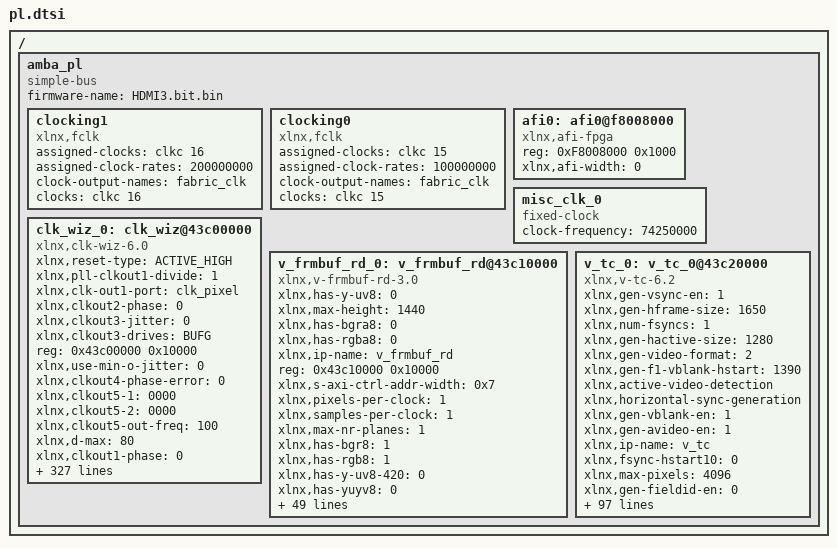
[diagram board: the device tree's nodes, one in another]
/ {
	amba_pl: amba_pl {
		ranges;
		compatible = "simple-bus";
		#address-cells = <1>;
		#size-cells = <1>;
		firmware-name = "HDMI3.bit.bin";
		clocking1: clocking1 {
			compatible = "xlnx,fclk";
			assigned-clocks = <&clkc 16>;
			assigned-clock-rates = <200000000>;
			#clock-cells = <0>;
			clock-output-names = "fabric_clk";
			clocks = <&clkc 16>;
		};
		clocking0: clocking0 {
			compatible = "xlnx,fclk";
			assigned-clocks = <&clkc 15>;
			assigned-clock-rates = <100000000>;
			#clock-cells = <0>;
			clock-output-names = "fabric_clk";
			clocks = <&clkc 15>;
		};
		afi0: afi0@f8008000 {
			status = "okay";
			compatible = "xlnx,afi-fpga";
			#address-cells = <1>;
			reg = <0xF8008000 0x1000>;
			#size-cells = <0>;
			xlnx,afi-width = <0>;
		};
		misc_clk_0: misc_clk_0 {
			compatible = "fixed-clock";
			clock-frequency = <74250000>;
			#clock-cells = <0>;
		};
		clk_wiz_0: clk_wiz@43c00000 {
			xlnx,reset-type = "ACTIVE_HIGH";
			xlnx,pll-clkout1-divide = <1>;
			xlnx,clk-out1-port = "clk_pixel";
			xlnx,clkout2-phase = <0>;
			xlnx,clkout3-jitter = <0>;
			xlnx,clkout3-drives = "BUFG";
			reg = <0x43c00000 0x10000>;
			xlnx,use-min-o-jitter = <0>;
			xlnx,clkout4-phase-error = <0>;
			xlnx,clkout5-1 = <0000>;
			xlnx,clkout5-2 = <0000>;
			xlnx,clkout5-out-freq = <100>;
			xlnx,d-max = <80>;
			xlnx,clkout1-phase = <0>;
			xlnx,divide6-auto = <0x186a0>;
			xlnx,clkout1-jitter = <0x141f9c80>;
			xlnx,clkfb-in-n-port = "clkfb_in_n";
			xlnx,clkout2-requested-out-freq = <0x1620d350>;
			xlnx,use-locked = <1>;
			xlnx,pll-clkout5-duty-cycle = <0x7a120>;
			xlnx,mmcm-clkout3-use-fine-ps;
			xlnx,clkout1-drives = "BUFG";
			xlnx,input-clk-stopped-port = "input_clk_stopped";
			xlnx,clkout4-duty-cycle = <50>;
			xlnx,divide3-auto = <0x186a0>;
			xlnx,use-dyn-reconfig = <1>;
			xlnx,clkout3-actual-freq = <100>;
			xlnx,clkout6-requested-duty-cycle = <50>;
			xlnx,diff-clk-in1-board-interface = "Custom";
			xlnx,mmcm-clkout0-duty-cycle = <0x7a120>;
			xlnx,clkin2-jitter-ps = <100>;
			xlnx,clkout2-1 = <0000>;
			xlnx,in-freq-units = "Units_MHz";
			xlnx,clkout2-2 = <0000>;
			xlnx,feedback-source = "FDBK_AUTO";
			xlnx,clkout5-requested-out-freq = <100>;
			xlnx,name = "clk_wiz_0";
			xlnx,prim-in-freq = <100>;
			xlnx,mmcm-clkout5-divide = <1>;
			xlnx,clkout3-phase-error = <0>;
			xlnx,clk-in2-board-interface = "Custom";
			xlnx,clkin1-ui-jitter = <0x2710>;
			xlnx,use-inclk-switchover = <0>;
			clock-names = "clk_in1" , "s_axi_aclk";
			xlnx,clkout5-duty-cycle = <50>;
			xlnx,use-clkout4-bar = <0>;
			xlnx,mmcm-clkout1-duty-cycle = <0x7a120>;
			xlnx,mmcm-clkout2-use-fine-ps;
			xlnx,clkout2-out-freq = <0x1620d350>;
			xlnx,use-dyn-phase-shift = <0>;
			xlnx,mmcm-clkout3-divide = <1>;
			xlnx,clkout2-actual-freq = <100>;
			xlnx,o-min = <1>;
			xlnx,daddr-port = "daddr";
			xlnx,precision = <1>;
			xlnx,mmcm-ref-jitter1 = <0x2710>;
			clock-output-names = "0x43c00000-clk_pixel 0x43c00000-Serial_Clock";
			xlnx,mmcm-ref-jitter2 = <0x2710>;
			xlnx,pll-notes = "No , notes";
			xlnx,use-phase-alignment = <1>;
			xlnx,ref-clk-freq = <100>;
			xlnx,clkout7-requested-duty-cycle = <50>;
			xlnx,inclk-sum-row0 = "Input , Clock , Freq , (MHz) , Input , Jitter , (UI)";
			xlnx,inclk-sum-row1 = "__primary_________100.000____________0.010";
			xlnx,use-fast-simulation = <0>;
			xlnx,inclk-sum-row2 = "no_secondary_input_clock";
			xlnx,mmcm-clkout1-divide = <2>;
			xlnx,din-port = "din";
			xlnx,reset-board-interface = "Custom";
			xlnx,clkout6-duty-cycle = <50>;
			xlnx,clkout2-phase-error = <0x134092d8>;
			xlnx,clkout1-requested-duty-cycle = <50>;
			xlnx,vco-max = <1200>;
			xlnx,use-freq-synth = <1>;
			xlnx,primtype-sel = "AUTO";
			xlnx,mmcm-clkout2-duty-cycle = <0x7a120>;
			xlnx,clkout5-used = <0>;
			xlnx,d-min = <1>;
			xlnx,pll-clkfbout-mult = <1>;
			xlnx,mmcm-clkout4-cascade;
			xlnx,use-clkout1-bar = <0>;
			xlnx,clk-out6-port = "clk_out6";
			xlnx,clkout2-sequence-number = <1>;
			xlnx,clk-valid-port = "CLK_VALID";
			xlnx,clkout2-used = <1>;
			xlnx,clkout4-sequence-number = <1>;
			xlnx,psincdec-port = "psincdec";
			xlnx,mmcm-clkout1-use-fine-ps;
			xlnx,clk-out3-port = "clk_out3";
			xlnx,clkout6-sequence-number = <1>;
			xlnx,platform = "UNKNOWN";
			xlnx,mmcm-clkout6-phase = <0>;
			xlnx,clkout1-actual-freq = <0x1620d350>;
			xlnx,clkout6-out-freq = <100>;
			xlnx,nr-outputs = <2>;
			xlnx,mmcm-clkin2-period = <10>;
			xlnx,prim-in-jitter = <0x2710>;
			xlnx,mmcm-clkfbout-mult-f = <0x2367b88>;
			status = "okay";
			xlnx,clkout6-1 = <0000>;
			xlnx,clkout6-2 = <0000>;
			xlnx,clkout7-duty-cycle = <50>;
			xlnx,outclk-sum-row1 = "clk_pixel__74.25000______0.000______50.0______337.616____322.999";
			xlnx,outclk-sum-row2 = "Serial_Clock__371.25000______0.000______50.0______258.703____322.999";
			xlnx,jitter-sel = "No_Jitter";
			xlnx,outclk-sum-row3 = "no_CLK_OUT3_output";
			xlnx,mmcm-clkout5-phase = <0>;
			xlnx,mmcm-clkout3-duty-cycle = <0x7a120>;
			xlnx,outclk-sum-row4 = "no_CLK_OUT4_output";
			xlnx,clkfb-in-p-port = "clkfb_in_p";
			xlnx,outclk-sum-row5 = "no_CLK_OUT5_output";
			xlnx,outclk-sum-row6 = "no_CLK_OUT6_output";
			xlnx,outclk-sum-row7 = "no_CLK_OUT7_output";
			xlnx,clkout1-phase-error = <0x134092d8>;
			xlnx,divide5-auto = <0x186a0>;
			xlnx,pll-bandwidth = "OPTIMIZED";
			xlnx,psdone-port = "psdone";
			xlnx,clkout3-1 = <0000>;
			xlnx,edk-iptype = "PERIPHERAL";
			xlnx,clkout3-2 = <0000>;
			xlnx,clkout3-requested-out-freq = <100>;
			xlnx,pll-clkout4-divide = <1>;
			xlnx,pll-clkfbout-phase = <0>;
			xlnx,divide2-auto = <0x30d40>;
			xlnx,override-mmcm = <0>;
			xlnx,clkout6-jitter = <0>;
			xlnx,ss-mode = "CENTER_HIGH";
			xlnx,mmcm-notes = "None";
			xlnx,clkout6-drives = "BUFG";
			xlnx,mmcm-clkfbout-use-fine-ps;
			xlnx,mmcm-clkout0-use-fine-ps;
			xlnx,ss-mod-period = <4000>;
			xlnx,mmcm-clkout4-phase = <0>;
			xlnx,clkout2-requested-duty-cycle = <50>;
			xlnx,clkout0-actual-freq = <0x46cf710>;
			xlnx,divclk = <0000>;
			xlnx,primary-port = "clk_in1";
			xlnx,mmcm-compensation = "ZHOLD";
			xlnx,clkout6-requested-out-freq = <100>;
			xlnx,clkout0-1 = <0000>;
			xlnx,clkout0-2 = <0000>;
			xlnx,clkout2-requested-phase = <0>;
			xlnx,relative-inclk = "REL_PRIMARY";
			xlnx,pll-clkout2-divide = <1>;
			xlnx,clkout4-requested-phase = <0>;
			xlnx,enable-user-clock0 = <0>;
			xlnx,filter-1 = <0000>;
			xlnx,mmcm-clkout4-duty-cycle = <0x7a120>;
			xlnx,clkout3-out-freq = <100>;
			xlnx,clkout4-jitter = <0>;
			xlnx,clkout6-requested-phase = <0>;
			xlnx,clkoutphy-requested-freq = <600>;
			xlnx,enable-user-clock1 = <0>;
			xlnx,filter-2 = <0000>;
			xlnx,ss-mod-freq = <250>;
			xlnx,in-jitter-units = "Units_UI";
			xlnx,mmcm-divclk-divide = <5>;
			xlnx,enable-user-clock2 = <0>;
			xlnx,enable-user-clock3 = <0>;
			xlnx,lock-1 = <0000>;
			xlnx,clkout4-drives = "BUFG";
			xlnx,lock-2 = <0000>;
			xlnx,den-port = "den";
			xlnx,lock-3 = <0000>;
			xlnx,use-safe-clock-startup = <0>;
			xlnx,mmcm-clkout3-phase = <0>;
			xlnx,dwe-port = "dwe";
			xlnx,clkfb-out-n-port = "clkfb_out_n";
			xlnx,use-max-i-jitter = <0>;
			xlnx,drdy-port = "drdy";
			xlnx,vco-min = <600>;
			xlnx,pll-clkout0-divide = <1>;
			xlnx,clkin1-jitter-ps = <100>;
			xlnx,clk-in-sel-port = "clk_in_sel";
			xlnx,use-freeze = <0>;
			xlnx,clkout2-jitter = <0xf6b7e97>;
			xlnx,enable-pll0 = <0>;
			xlnx,enable-pll1 = <0>;
			xlnx,clkout2-drives = "BUFG";
			xlnx,use-inclk-stopped = <0>;
			xlnx,use-clkout3-bar = <0>;
			xlnx,use-clk-valid = <0>;
			xlnx,mmcm-clkout2-phase = <0>;
			compatible = "xlnx,clk-wiz-6.0" , "xlnx,clocking-wizard";
			xlnx,reset-port = "reset";
			xlnx,mmcm-clkout5-duty-cycle = <0x7a120>;
			xlnx,mmcm-clkout0-divide-f = <10>;
			xlnx,pll-clkout0-duty-cycle = <0x7a120>;
			xlnx,speed-grade = <1>;
			xlnx,diff-clk-in2-board-interface = "Custom";
			xlnx,clkout3-requested-duty-cycle = <50>;
			xlnx,use-status = <0>;
			xlnx,prim-source = "Single_ended_clock_capable_pin";
			xlnx,clkout7-used = <0>;
			xlnx,use-clkfb-stopped = <0>;
			xlnx,mmcm-clkout1-phase = <0>;
			xlnx,mmcm-clkout6-divide = <1>;
			xlnx,clkout7-out-freq = <100>;
			xlnx,prim-in-timeperiod = <10>;
			xlnx,clkout4-used = <0>;
			xlnx,pll-clkin-period = <1>;
			xlnx,clk-out5-port = "clk_out5";
			xlnx,psclk-port = "psclk";
			xlnx,primitive = "MMCM";
			xlnx,clkout1-used;
			xlnx,reset-low = <0>;
			xlnx,clk-in1-board-interface = "Custom";
			xlnx,clk-out2-port = "Serial_Clock";
			xlnx,power-down-port = "power_down";
			xlnx,clkout7-phase-error = <0>;
			xlnx,mmcm-clkout6-duty-cycle = <0x7a120>;
			xlnx,mmcm-clkout4-divide = <1>;
			xlnx,mmcm-clkfbout-phase = <0>;
			xlnx,mmcm-clkout0-phase = <0>;
			xlnx,pll-clkout1-duty-cycle = <0x7a120>;
			xlnx,user-clk-freq0 = <100>;
			xlnx,user-clk-freq1 = <100>;
			xlnx,pll-clkout5-phase = <0>;
			xlnx,user-clk-freq2 = <100>;
			xlnx,secondary-in-jitter = <0x2710>;
			xlnx,user-clk-freq3 = <100>;
			xlnx,use-clock-sequencing = <0>;
			xlnx,secondary-source = "Single_ended_clock_capable_pin";
			xlnx,cddcdone-port = "cddcdone";
			xlnx,clkout7-phase = <0>;
			xlnx,psen-port = "psen";
			xlnx,mmcm-clkout6-use-fine-ps;
			xlnx,dclk-port = "dclk";
			xlnx,m-max = <64>;
			xlnx,outclk-sum-row0a = "Output , Output , Phase , Duty , Cycle , Pk-to-Pk , Phase";
			xlnx,clkout1-requested-out-freq = <0x46cf710>;
			xlnx,clkout6-actual-freq = <100>;
			xlnx,divide7-auto = <0x186a0>;
			xlnx,outclk-sum-row0b = "Clock , Freq , (MHz) , (degrees) , (%) , Jitter , (ps) , Error , (ps)";
			xlnx,clkout4-1 = <0000>;
			xlnx,locked-port = "locked";
			xlnx,clkin2-ui-jitter = <0x2710>;
			xlnx,clkout4-2 = <0000>;
			xlnx,enable-clock-monitor = <0>;
			xlnx,mmcm-clkout2-divide = <1>;
			xlnx,ss-mod-time = <0xfa0>;
			xlnx,auto-primitive = "MMCM";
			xlnx,divide4-auto = <0x186a0>;
			xlnx,pll-clkout4-phase = <0>;
			xlnx,use-power-down = <0>;
			xlnx,mmcm-startup-wait;
			xlnx,divide1-auto = <1>;
			xlnx,clkout4-requested-duty-cycle = <50>;
			xlnx,clkout4-requested-out-freq = <100>;
			xlnx,optimize-clocking-structure-en = <0>;
			xlnx,clkout4-out-freq = <100>;
			xlnx,clkout6-phase = <0>;
			xlnx,num-out-clks = <2>;
			xlnx,ip-name = "clk_wiz";
			xlnx,pll-clkout2-duty-cycle = <0x7a120>;
			xlnx,clkout1-1 = <0000>;
			xlnx,clkout1-2 = <0000>;
			xlnx,clkout1-duty-cycle = <50>;
			xlnx,pll-divclk-divide = <1>;
			xlnx,clkout6-phase-error = <0>;
			xlnx,dout-port = "dout";
			xlnx,clkout1-sequence-number = <1>;
			xlnx,pll-clkout3-phase = <0>;
			xlnx,cddcreq-port = "cddcreq";
			xlnx,clkout7-requested-out-freq = <100>;
			xlnx,use-spread-spectrum = <0>;
			xlnx,clkout3-sequence-number = <1>;
			xlnx,clkout5-sequence-number = <1>;
			xlnx,summary-strings = "empty";
			xlnx,pll-compensation = "SYSTEM_SYNCHRONOUS";
			xlnx,clkout5-phase = <0>;
			xlnx,clkout7-sequence-number = <1>;
			xlnx,status-port = "STATUS";
			xlnx,clkfb-out-p-port = "clkfb_out_p";
			xlnx,mmcm-clkout5-use-fine-ps;
			xlnx,clkfb-in-port = "clkfb_in";
			xlnx,clkout5-actual-freq = <100>;
			xlnx,input-mode = "frequency";
			xlnx,interface-selection = <1>;
			xlnx,mmcm-bandwidth = "OPTIMIZED";
			xlnx,calc-done = "empty";
			xlnx,pll-clkout2-phase = <0>;
			xlnx,has-cddc = <0>;
			xlnx,power-reg = <0000>;
			xlnx,mmcm-clkin1-period = <10>;
			xlnx,pll-clkout3-duty-cycle = <0x7a120>;
			xlnx,clkout2-duty-cycle = <50>;
			xlnx,clkout4-phase = <0>;
			xlnx,pll-clkout5-divide = <1>;
			xlnx,clkout7-jitter = <0>;
			clocks = <&clkc 15>, <&clkc 15>;
			xlnx,clkout1-out-freq = <0x46cf710>;
			xlnx,clkout7-drives = "BUFG";
			xlnx,clkout5-phase-error = <0>;
			xlnx,pll-clkout1-phase = <0>;
			xlnx,clkout5-requested-duty-cycle = <50>;
			xlnx,clkfb-in-signaling = "SINGLE";
			xlnx,enable-clkoutphy = <0>;
			xlnx,use-clkout2-bar = <0>;
			xlnx,secondary-port = "clk_in2";
			xlnx,clkout3-phase = <0>;
			xlnx,pll-clkout3-divide = <1>;
			xlnx,use-reset = <1>;
			xlnx,override-pll = <0>;
			xlnx,clkoutphy-mode = "VCO";
			xlnx,mmcm-clkout4-use-fine-ps;
			xlnx,clkout5-jitter = <0>;
			xlnx,clkout6-used = <0>;
			xlnx,m-min = <2>;
			xlnx,mmcm-clock-hold;
			xlnx,clkfb-stopped-port = "clkfb_stopped";
			xlnx,clk-out7-port = "clk_out7";
			xlnx,clkout1-requested-phase = <0>;
			xlnx,clkout4-actual-freq = <100>;
			xlnx,pll-clk-feedback = "CLKFBOUT";
			xlnx,phaseshift-mode = "WAVEFORM";
			xlnx,clkfb-out-port = "clkfb_out";
			xlnx,clkout5-drives = "BUFG";
			xlnx,o-max = <128>;
			xlnx,clkout3-requested-phase = <0>;
			xlnx,jitter-options = "UI";
			xlnx,secondary-in-timeperiod = <10>;
			xlnx,pll-clkout4-duty-cycle = <0x7a120>;
			xlnx,clkout3-used = <0>;
			xlnx,clkout5-requested-phase = <0>;
			xlnx,pll-clkout0-phase = <0>;
			xlnx,clk-out4-port = "clk_out4";
			xlnx,clkout3-duty-cycle = <50>;
			xlnx,clkout7-requested-phase = <0>;
			xlnx,secondary-in-freq = <100>;
			xlnx,use-min-power = <0>;
			xlnx,clkfbout-1 = <0000>;
			#clock-cells = <1>;
			xlnx,pll-ref-jitter = <0x2710>;
			xlnx,clkfbout-2 = <0000>;
			xlnx,component-name = "system_clk_wiz_0_0";
		};
		v_frmbuf_rd_0: v_frmbuf_rd@43c10000 {
			xlnx,has-y-uv8 = <0>;
			xlnx,max-height = <1440>;
			xlnx,has-bgra8 = <0>;
			xlnx,has-rgba8 = <0>;
			xlnx,ip-name = "v_frmbuf_rd";
			reg = <0x43c10000 0x10000>;
			xlnx,s-axi-ctrl-addr-width = <0x7>;
			xlnx,pixels-per-clock = <1>;
			xlnx,samples-per-clock = <1>;
			xlnx,max-nr-planes = <1>;
			xlnx,has-bgr8 = <1>;
			xlnx,has-rgb8 = <1>;
			xlnx,has-y-uv8-420 = <0>;
			xlnx,has-yuyv8 = <0>;
			xlnx,has-y-u-v8 = <0>;
			interrupt-names = "interrupt";
			compatible = "xlnx,v-frmbuf-rd-3.0" , "xlnx,axi-frmbuf-rd-v2.2";
			xlnx,max-width = <2560>;
			xlnx,has-rgb16 = <0>;
			xlnx,vid-formats = "rgb888" , "bgr888";
			xlnx,has-bgrx8 = <0>;
			xlnx,has-rgbx8 = <0>;
			xlnx,has-rgbx10 = <0>;
			interrupt-parent = <&intc>;
			xlnx,aximm-num-outstanding = <4>;
			xlnx,has-uyvy8 = <0>;
			xlnx,use-uram = <0>;
			xlnx,has-rgbx12 = <0>;
			xlnx,aximm-burst-length = <16>;
			xlnx,aximm-addr-width = <32>;
			xlnx,video-width = <8>;
			xlnx,max-cols = <2560>;
			xlnx,has-yuv8 = <0>;
			status = "okay";
			xlnx,has-y-uv10-420 = <0>;
			xlnx,has-yuva8 = <0>;
			xlnx,has-y-uv12-420 = <0>;
			xlnx,name = "v_frmbuf_rd_0";
			interrupts = < 0 29 4 >;
			xlnx,has-y10 = <0>;
			xlnx,has-y-uv16-420 = <0>;
			xlnx,has-y12 = <0>;
			xlnx,has-alpha = <0>;
			xlnx,has-y-u-v10 = <0>;
			clocks = <&clkc 15>;
			xlnx,has-y16 = <0>;
			xlnx,dma-align = <8>;
			xlnx,has-y-u-v12 = <0>;
			xlnx,edk-iptype = "PERIPHERAL";
			xlnx,has-interlaced = <0>;
			xlnx,has-yuv16 = <0>;
			xlnx,has-yuvx8 = <0>;
			xlnx,is-tile-format = <0>;
			xlnx,dma-addr-width = <32>;
			clock-names = "ap_clk";
			xlnx,s-axi-ctrl-data-width = <0x20>;
			xlnx,has-y8 = <0>;
			xlnx,has-y-uv10 = <0>;
			xlnx,has-y-uv12 = <0>;
			xlnx,max-rows = <1440>;
			xlnx,has-yuvx10 = <0>;
			#dma-cells = <1>;
			xlnx,has-yuvx12 = <0>;
			xlnx,has-y-uv16 = <0>;
			xlnx,max-data-width = <8>;
			xlnx,has-y-u-v8-420 = <0>;
			xlnx,num-video-components = <3>;
			xlnx,aximm-data-width = <64>;
		};
		v_tc_0: v_tc_0@43c20000 {
			xlnx,gen-vsync-en = <1>;
			xlnx,gen-hframe-size = <1650>;
			xlnx,num-fsyncs = <1>;
			xlnx,gen-hactive-size = <1280>;
			xlnx,gen-video-format = <2>;
			xlnx,gen-f1-vblank-hstart = <1390>;
			xlnx,active-video-detection;
			xlnx,horizontal-sync-generation;
			xlnx,gen-vblank-en = <1>;
			xlnx,gen-avideo-en = <1>;
			xlnx,ip-name = "v_tc";
			xlnx,fsync-hstart10 = <0>;
			xlnx,max-pixels = <4096>;
			xlnx,gen-fieldid-en = <0>;
			reg = <0x43c20000 0x10000>;
			xlnx,det-vblank-en = <1>;
			xlnx,fsync-hstart11 = <0>;
			xlnx,fsync-hstart12 = <0>;
			xlnx,pixels-per-clock = <0x4>;
			xlnx,gen-interlaced = <0>;
			xlnx,det-avideo-en = <1>;
			xlnx,fsync-hstart13 = <0>;
			xlnx,fsync-hstart14 = <0>;
			xlnx,gen-f0-vblank-hend = <1390>;
			xlnx,fsync-hstart15 = <0>;
			xlnx,det-hsync-en = <1>;
			interrupt-names = "irq";
			xlnx,enable-generation;
			xlnx,gen-avideo-polarity = <1>;
			xlnx,max-lines-per-frame = <4096>;
			xlnx,has-axi4-lite = <1>;
			compatible = "xlnx,v-tc-6.2" , "xlnx,bridge-v-tc-6.1";
			xlnx,max-clocks-per-line = <4096>;
			xlnx,gen-f0-vframe-size = <750>;
			xlnx,gen-f0-vblank-hstart = <1390>;
			interrupt-parent = <&intc>;
			xlnx,max-lines = <4096>;
			xlnx,gen-f0-vsync-vstart = <724>;
			xlnx,horizontal-blank-generation;
			xlnx,gen-hsync-end = <1430>;
			xlnx,gen-f0-vsync-hstart = <1390>;
			xlnx,gen-f1-vsync-hend = <1390>;
			xlnx,vertical-blank-detection;
			xlnx,gen-vsync-polarity = <1>;
			xlnx,fsync-vstart0 = <0>;
			xlnx,gen-hsync-polarity = <1>;
			xlnx,fsync-vstart1 = <0>;
			status = "okay";
			xlnx,fsync-vstart2 = <0>;
			xlnx,gen-hsync-start = <1390>;
			xlnx,gen-f0-vsync-vend = <729>;
			xlnx,fsync-vstart3 = <0>;
			xlnx,vertical-sync-detection;
			xlnx,frame-syncs = <1>;
			xlnx,fsync-vstart4 = <0>;
			xlnx,gen-vactive-size = <720>;
			xlnx,name = "v_tc_0";
			xlnx,fsync-vstart5 = <0>;
			interrupts = < 0 30 4 >;
			xlnx,gen-achroma-en = <0>;
			xlnx,fsync-vstart6 = <0>;
			xlnx,det-fieldid-en = <0>;
			xlnx,fsync-vstart7 = <0>;
			xlnx,gen-hsync-en = <1>;
			xlnx,fsync-vstart8 = <0>;
			xlnx,fsync-vstart10 = <0>;
			xlnx,fsync-vstart9 = <0>;
			xlnx,fsync-vstart11 = <0>;
			xlnx,arbitrary-res-en = /bits/ 8 <0x0>;
			xlnx,fsync-vstart12 = <0>;
			xlnx,fsync-vstart13 = <0>;
			clocks = <&misc_clk_0>, <&clkc 15>;
			xlnx,fsync-vstart14 = <0>;
			xlnx,fsync-vstart15 = <0>;
			xlnx,gen-cparity = <0>;
			xlnx,edk-iptype = "PERIPHERAL";
			xlnx,vertical-sync-generation;
			xlnx,gen-f1-vblank-hend = <1390>;
			xlnx,det-vsync-en = <1>;
			xlnx,gen-vblank-polarity = <1>;
			xlnx,fsync-hstart0 = <0>;
			clock-names = "clk" , "s_axi_aclk";
			xlnx,interlace-en = <0>;
			xlnx,gen-auto-switch = <0>;
			xlnx,fsync-hstart1 = <0>;
			xlnx,fsync-hstart2 = <0>;
			xlnx,active-video-generation;
			xlnx,fsync-hstart3 = <0>;
			xlnx,fsync-hstart4 = <0>;
			xlnx,horizontal-blank-detection;
			xlnx,fsync-hstart5 = <0>;
			xlnx,gen-f1-vframe-size = <750>;
			xlnx,fsync-hstart6 = <0>;
			xlnx,fsync-hstart7 = <0>;
			xlnx,fsync-hstart8 = <0>;
			xlnx,gen-hblank-en = <1>;
			xlnx,fsync-hstart9 = <0>;
			xlnx,horizontal-sync-detection;
			xlnx,gen-f1-vsync-vend = <729>;
			xlnx,detect-en = <0>;
			xlnx,det-hblank-en = <1>;
			xlnx,vid-ppc = <4>;
			xlnx,has-intc-if = <0>;
			xlnx,generate-en = <1>;
			xlnx,gen-achroma-polarity = <1>;
			xlnx,sync-en = <0>;
			xlnx,det-achroma-en = <0>;
			xlnx,generator;
			xlnx,gen-f1-vsync-vstart = <724>;
			xlnx,vertical-blank-generation;
			xlnx,gen-hblank-polarity = <1>;
			xlnx,video-mode = "720p";
			xlnx,gen-fieldid-polarity = <1>;
			xlnx,gen-f1-vsync-hstart = <1390>;
			xlnx,gen-f0-vsync-hend = <1390>;
		};
	};
};
